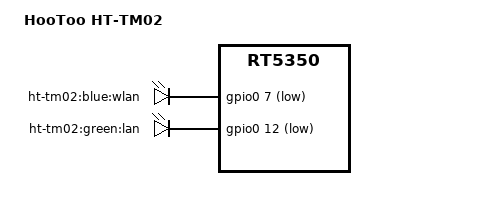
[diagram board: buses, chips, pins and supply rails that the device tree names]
#include "rt5350_sunvalley_tripmate.dtsi"

/ {
	compatible = "hootoo,ht-tm02", "ralink,rt5350-soc";
	model = "HooToo HT-TM02";

	aliases {
		led-boot = &led_wlan;
		led-failsafe = &led_wlan;
		led-running = &led_wlan;
		led-upgrade = &led_wlan;
	};

	leds {
		compatible = "gpio-leds";

		led_wlan: wlan {
			label = "ht-tm02:blue:wlan";
			gpios = <&gpio0 7 GPIO_ACTIVE_LOW>;
		};

		lan {
			label = "ht-tm02:green:lan";
			gpios = <&gpio0 12 GPIO_ACTIVE_LOW>;
		};
	};
};

&gpio0 {
	status = "okay";
};

&sunvalley_keys {
	modeswitch {
		label = "modeswitch";
		gpios = <&gpio0 14 GPIO_ACTIVE_LOW>;
		linux,code = <BTN_0>;
		linux,input-type = <EV_SW>;
	};
};
